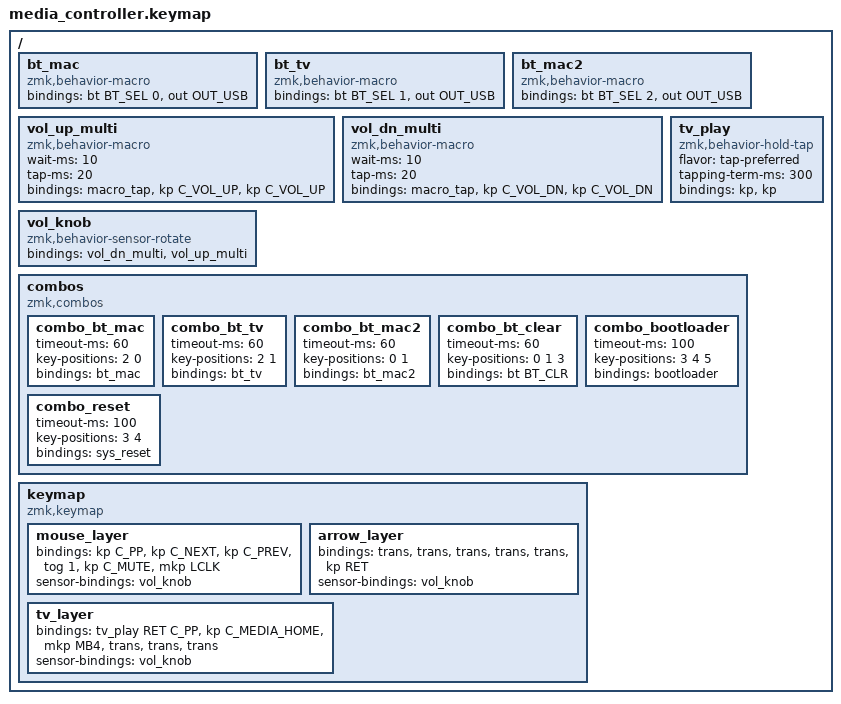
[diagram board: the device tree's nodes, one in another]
/*
 * Media Controller keymap
 *
 * Layout (physical positions 0-5):
 *   0: play/pause (D16)   1: next (D10)   2: prev (A3)
 *   3: mode-toggle (D3)   4: encoder push / mute (D2)   5: joystick push (A0)
 *   encoder turn: volume up / down (all layers)
 *
 * Bluetooth profiles, each picked with a combo:
 *   hold prev + play               -> Bluetooth profile 0 (Mac)
 *   hold prev + next               -> Bluetooth profile 1 (Android TV)
 *   hold play + next               -> Bluetooth profile 2 (second Mac)
 *   hold play + next + mode-toggle -> forget the current BT profile's pairing
 *
 * Maintenance combos (buttons not used by the profile combos above):
 *   hold mode-toggle + mute + joy-push -> flashing (UF2 bootloader) mode
 *   hold mode-toggle + mute            -> restart (re-measures the joystick
 *                                         center 2s later - hands off)
 * USB always wins: whenever a cable to a computer is plugged in, output
 * goes over USB, whatever profile is selected; unplugged, it goes to the
 * selected BT profile. The profile combos also set ZMK's (persisted)
 * preferred output back to USB, in case an older firmware saved BLE.
 *
 * What the next/prev buttons send depends on the active output:
 *   profiles 0, 2 and cable: media next / previous track
 *   profile 1 (TV):      next = Home, prev = Back (mouse button 4)
 *                        play: tap = Play/Pause, hold = Enter (OK)
 * That's the tv_layer below - it's switched on and off automatically by
 * src/endpoint_layer.c (CONFIG_ZMK_ENDPOINT_LAYER in
 * media_controller.conf) whenever the active output changes; there's no
 * keymap binding for it.
 *
 * TV keys:
 * back = mouse button 4 (MB4, a mouse's "back" side button). Android
 * turns it into the real system KEYCODE_BACK in its input reader, so no
 * app can swallow it. Escape was used before, but Android only maps
 * Escape to Back as a *fallback* when the focused app doesn't handle
 * Escape itself, so it worked in some apps and not others. The TV
 * remote's own Back (Consumer AC Back, 0x224) needs Full consumer
 * usages, which broke the other media keys on this TV.
 * home = Consumer "Media Select Home" (0x9A), within the Basic
 * consumer-usage range (see CONFIG_ZMK_HID_CONSUMER_REPORT_USAGES_BASIC
 * in media_controller.conf), unlike AC Home (0x223), which needs Full
 * and would reintroduce the Android compatibility issue Basic mode fixed.
 * NOTE: reported not to actually trigger Home on this TV - see README.
 *
 * joystick push in mouse mode is a plain left-click (held while
 * pressed, so dragging works) on every output, TV included. It used to
 * also send Enter as a fallback for the TV, but that made every click
 * on a Mac press Enter too. Being re-tested on the TV: if clicks don't
 * register there, put a click + Enter binding in tv_layer only.
 *
 * Joystick modes, toggled by the mode-toggle button:
 *   Layer 0 (mouse mode, default): joystick tilt moves the mouse
 *     cursor, joystick push = left-click.
 *   Layer 1 (arrow mode): joystick tilt sends arrow-key presses
 *     (held while tilted, released when centered), joystick push =
 *     Enter. The tilt behavior switch happens inside
 *     drivers/input/analog_joystick.c (it watches whether layer 1 is
 *     active), since the joystick isn't a keymap position.
 * Layer order matters: mouse_layer = 0, arrow_layer = 1 (must match the
 * joystick's arrow-layer in the overlay), tv_layer = 2 (must match
 * CONFIG_ZMK_ENDPOINT_LAYER_INDEX, default 2). tv_layer is highest so
 * its next/prev override both joystick modes.
 */

#include <behaviors.dtsi>
#include <dt-bindings/zmk/keys.h>
#include <dt-bindings/zmk/bt.h>
#include <dt-bindings/zmk/outputs.h>
#include <dt-bindings/zmk/mouse.h>

/ {
    bt_mac: bt_mac {
        compatible = "zmk,behavior-macro";
        #binding-cells = <0>;
        bindings = <&bt BT_SEL 0>, <&out OUT_USB>;
    };

    bt_tv: bt_tv {
        compatible = "zmk,behavior-macro";
        #binding-cells = <0>;
        bindings = <&bt BT_SEL 1>, <&out OUT_USB>;
    };

    bt_mac2: bt_mac2 {
        compatible = "zmk,behavior-macro";
        #binding-cells = <0>;
        bindings = <&bt BT_SEL 2>, <&out OUT_USB>;
    };

    /*
     * Volume knob: each encoder detent sends two volume presses
     * instead of one, so 0 -> 100 on the TV takes ~1.5 turns instead
     * of 3. Repeating presses inside a macro (rather than raising
     * triggers-per-rotation in the overlay) keeps every trigger on a
     * detent, so a knob resting between clicks can't jitter the volume.
     * Raise/lower the number of &kp taps to tune speed.
     */
    vol_up_multi: vol_up_multi {
        compatible = "zmk,behavior-macro";
        #binding-cells = <0>;
        wait-ms = <10>;
        tap-ms = <20>;
        bindings = <&macro_tap &kp C_VOL_UP &kp C_VOL_UP>;
    };

    vol_dn_multi: vol_dn_multi {
        compatible = "zmk,behavior-macro";
        #binding-cells = <0>;
        wait-ms = <10>;
        tap-ms = <20>;
        bindings = <&macro_tap &kp C_VOL_DN &kp C_VOL_DN>;
    };

    // Same direction as the old <&inc_dec_kp C_VOL_DN C_VOL_UP>.
    vol_knob: vol_knob {
        compatible = "zmk,behavior-sensor-rotate";
        #sensor-binding-cells = <0>;
        bindings = <&vol_dn_multi>, <&vol_up_multi>;
    };

    /*
     * TV play button: tap = media Play/Pause, hold = Enter (OK).
     * Android sends Play/Pause to the active media session, not
     * necessarily the app on screen, and many TV apps only pause on the
     * remote's OK button - hold gives that as a fallback. Not both at
     * once: apps that handle both would toggle twice and look dead.
     */
    tv_play: tv_play {
        compatible = "zmk,behavior-hold-tap";
        #binding-cells = <2>;
        flavor = "tap-preferred";
        tapping-term-ms = <300>;
        bindings = <&kp>, <&kp>;
    };

    combos {
        compatible = "zmk,combos";

        combo_bt_mac {
            timeout-ms = <60>;
            key-positions = <2 0>;  // prev + play
            bindings = <&bt_mac>;
        };

        combo_bt_tv {
            timeout-ms = <60>;
            key-positions = <2 1>;  // prev + next
            bindings = <&bt_tv>;
        };

        combo_bt_mac2 {
            timeout-ms = <60>;
            key-positions = <0 1>;  // play + next
            bindings = <&bt_mac2>;
        };

        combo_bt_clear {
            timeout-ms = <60>;
            key-positions = <0 1 3>;  // play + next + mode-toggle
            bindings = <&bt BT_CLR>;
        };

        /* Same as double-tapping reset: the NICENANO drive appears (when
         * USB is connected). Reset pin still works as a fallback. */
        combo_bootloader {
            timeout-ms = <100>;
            key-positions = <3 4 5>;  // mode-toggle + mute + joy-push
            bindings = <&bootloader>;
        };

        combo_reset {
            timeout-ms = <100>;
            key-positions = <3 4>;  // mode-toggle + mute
            bindings = <&sys_reset>;
        };
    };

    keymap {
        compatible = "zmk,keymap";

        mouse_layer {
            bindings = <
                &kp C_PP   &kp C_NEXT   &kp C_PREV   &tog 1   &kp C_MUTE   &mkp LCLK
            >;

            sensor-bindings = <&vol_knob>;
        };

        arrow_layer {
            bindings = <
                &trans     &trans       &trans       &trans   &trans       &kp RET
            >;

            sensor-bindings = <&vol_knob>;
        };

        tv_layer {
            bindings = <
                &tv_play RET C_PP   &kp C_MEDIA_HOME   &mkp MB4   &trans   &trans   &trans
            >;

            sensor-bindings = <&vol_knob>;
        };
    };
};
